# max32665 register map
Vendor: Maxim-Integrated; Series: ARMCM3; File version: 1.1
CPU: CM4 r2p1, little endian, MPU, FPU, 3 interrupt priority bits
Registers are 32-bit, read-write, reset 0x0 unless marked. A register's access mark holds for its fields unless they carry their own. Offsets are from the block's base; [hi:lo] are bit positions; {n}, {i} and the like mark numbered series.

## MCR — Misc Control.
Base 0x40006C00
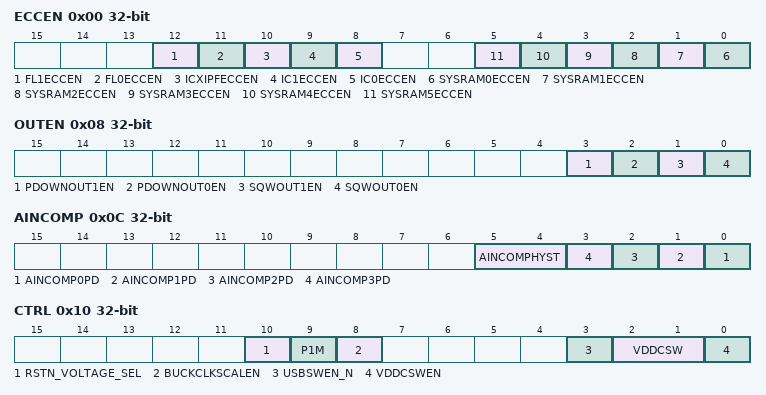
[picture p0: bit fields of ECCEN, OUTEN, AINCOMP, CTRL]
0x00 ECCEN — ECC Enable Register
  [all] fields
    0=dis (disabled.); 1=en (enabled.)
  [12] FL1ECCEN — Flash1 ECC Enable.
  [11] FL0ECCEN — Flash0 ECC Enable.
  [10] ICXIPFECCEN — IcacheXIP ECC Enable.
  [9] IC1ECCEN — Icache1 ECC Enable.
  [8] IC0ECCEN — Icache0 ECC Enable.
  [n] SYSRAM{n}ECCEN (n=0..5) — ECC System RAM Enable.
0x04 HIRC96M — 96MHz High Frequency Clock Adjustment Register
  [8:0] HIRC96MTR — HIRC96M Trim: Allow user to change 96M Frequency
    0x100=Default setting
0x08 OUTEN — GPIOOUT_EN Function Enable Register
  [all] fields
    0=dis (disabled.); 1=en (enabled.)
  [3] PDOWNOUT1EN — Allows PDOWN on GPIO0_26
  [2] PDOWNOUT0EN — Allows PDOWN on GPIO0_18
  [1] SQWOUT1EN — Allows SQWOUT on GPIO0_27
  [0] SQWOUT0EN — Allows SQWOUT on GPIO0_19
0x0C AINCOMP — Comparator Power Control Register
  [5:4] AINCOMPHYST — Set Hysteresis on Analog Comparators
  [n] AINCOMP{n}PD (n=0..3) — Power Down AIN Comp{n}
    0=on (power on); 1=off (power off)
0x10 CTRL — Misc Power State Control Register
  [10] RSTN_VOLTAGE_SEL — Error! Description not Found!
  [9] P1M — Enable the Reset Pad Pull Up Resistors
    0=1m (1MOhm Pullup); 1=25k (25kOhm Pullup.)
  [8] BUCKCLKSCALEN — Allows Dynamic scaling of SIMO clock, reduces power in LP Modes
    0=dis (disabled.); 1=en (enabled.)
  [3] USBSWEN_N — USB Switch Control
    1=off (USB SW off in LP modes); 0=on (USB SW On)
  [2:1] VDDCSW — Controls switching of VCORE
  [0] VDDCSWEN — Allows switching VDDC from VCOREA to VCOREB
    0=dis (disabled.); 1=en (enabled.)

## OWM — 1-Wire Master Interface.
Base 0x4003D000
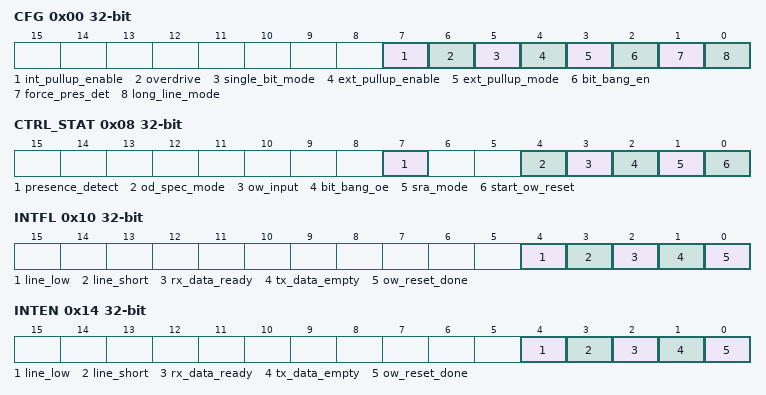
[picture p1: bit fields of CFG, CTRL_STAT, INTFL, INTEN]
0x00 CFG — 1-Wire Master Configuration.
  [7] int_pullup_enable — Enable intenral pullup.
  [6] overdrive — Enables overdrive speed for 1-Wire operations.
  [5] single_bit_mode — Enable Single Bit TX/RX Mode.
  [4] ext_pullup_enable — Enable External Pullup.
  [3] ext_pullup_mode — Provide an extra output control to control an external pullup.
  [2] bit_bang_en — Bit Bang Enable.
  [1] force_pres_det — Force Line During Presence Detect.
  [0] long_line_mode
0x04 CLK_DIV_1US — 1-Wire Master Clock Divisor.
  [7:0] divisor — Clock Divisor for 1Mhz.
0x08 CTRL_STAT — 1-Wire Master Control/Status.
  [7] presence_detect ro — Presence Pulse Detected.
  [4] od_spec_mode ro — Overdrive Spec Mode.
  [3] ow_input ro — OW Input State.
  [2] bit_bang_oe — Bit Bang Output Enable.
  [1] sra_mode
  [0] start_ow_reset
0x0C DATA — 1-Wire Master Data Buffer.
  [7:0] tx_rx — TX/RX Buffer.
0x10 INTFL — 1-Wire Master Interrupt Flags.
  [4] line_low — OW Line Low Detected Interrupt Flag.
  [3] line_short — OW Line Short Detected Interrupt Flag.
  [2] rx_data_ready — RX Data Ready Interrupt Flag
  [1] tx_data_empty — TX Data Empty Interrupt Flag.
  [0] ow_reset_done — OW Reset Sequence Completed.
0x14 INTEN — 1-Wire Master Interrupt Enables.
  [4] line_low write-1-clears — OW Line Low Detected Interrupt Enable.
  [3] line_short write-1-clears — OW Line Short Detected Interrupt Enable.
  [2] rx_data_ready write-1-clears — Rx Data Ready Interrupt Enable.
  [1] tx_data_empty write-1-clears — Tx Data Empty Interrupt Enable.
  [0] ow_reset_done write-1-clears — OW Reset Sequence Completed.

## PT — Pulse Train
Base 0x4003C020
Same registers: PT{n} {0x4003C020+0x10*n} (n=1..15)
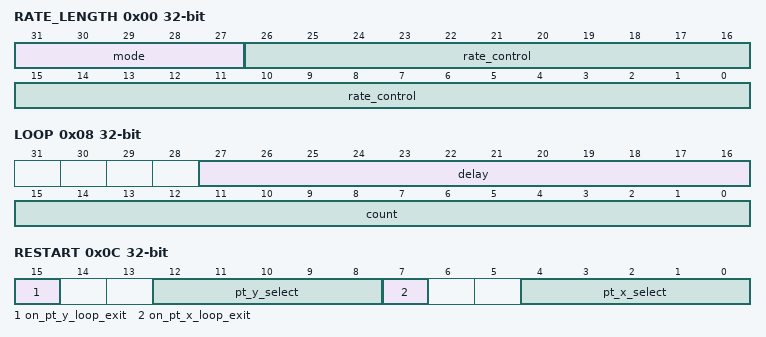
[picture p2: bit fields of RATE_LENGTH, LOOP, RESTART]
0x00 RATE_LENGTH — Pulse Train Configuration
  [31:27] mode — Pulse Train Output Mode/Train Length
    0=32_BIT (Pulse train, 32 bit pattern.); 1=SQUARE_WAVE (Square wave mode.); {v}={v}_BIT (Pulse train, {v} bit pattern.) (v=2..31)
  [26:0] rate_control — Pulse Train Enable and Rate Control. Set to 0 to disable the Pulse Train.
0x04 TRAIN — Write the repeating bit pattern that is shifted out, LSB first, when configured in Pulse Train mode. See PT_RATE_LENGTH.mode for setting the length.
0x08 LOOP — Pulse Train Loop Count
  [27:16] delay — Delay between loops of the Pulse Train in PT Peripheral Clock cycles
  [15:0] count — Number of loops for this pulse train to repeat.
0x0C RESTART — Pulse Train Auto-Restart Configuration.
  [15] on_pt_y_loop_exit — Enable Auto-Restart on PT Y Loop Exit
  [12:8] pt_y_select — Auto-Restart PT Y Select
  [7] on_pt_x_loop_exit — Enable Auto-Restart on PT X Loop Exit
  [4:0] pt_x_select — Auto-Restart PT X Select
